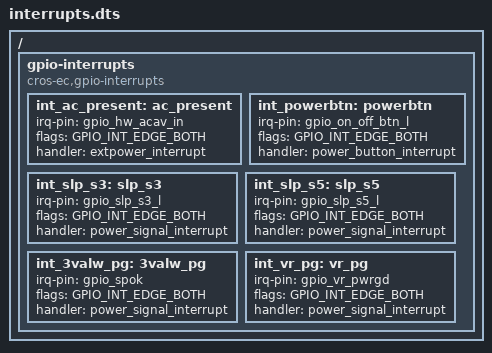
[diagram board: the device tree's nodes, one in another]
/* Copyright 2022 The ChromiumOS Authors
 * Use of this source code is governed by a BSD-style license that can be
 * found in the LICENSE file.
 */

/ {
	gpio-interrupts {
		compatible = "cros-ec,gpio-interrupts";

		int_ac_present: ac_present {
			irq-pin = <&gpio_hw_acav_in>;
			flags = <GPIO_INT_EDGE_BOTH>;
			handler = "extpower_interrupt";
		};
		int_powerbtn: powerbtn {
			irq-pin = <&gpio_on_off_btn_l>;
			flags = <GPIO_INT_EDGE_BOTH>;
			handler = "power_button_interrupt";
		};
		int_slp_s3: slp_s3 {
			irq-pin = <&gpio_slp_s3_l>;
			flags = <GPIO_INT_EDGE_BOTH>;
			handler = "power_signal_interrupt";
		};
		int_slp_s5: slp_s5 {
			irq-pin = <&gpio_slp_s5_l>;
			flags = <GPIO_INT_EDGE_BOTH>;
			handler = "power_signal_interrupt";
		};
		int_3valw_pg: 3valw_pg {
			irq-pin = <&gpio_spok>;
			flags = <GPIO_INT_EDGE_BOTH>;
			handler = "power_signal_interrupt";
		};
		int_vr_pg: vr_pg {
			irq-pin = <&gpio_vr_pwrgd>;
			flags = <GPIO_INT_EDGE_BOTH>;
			handler = "power_signal_interrupt";
		};
	};
};
